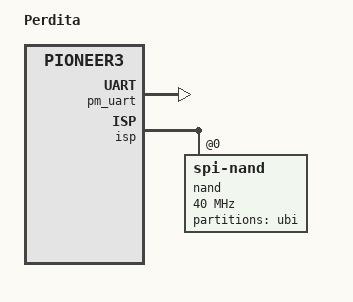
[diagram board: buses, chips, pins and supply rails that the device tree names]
// SPDX-License-Identifier: GPL-2.0
/*
 * Copyright (c) 2019 thingy.jp.
 * Author: Daniel Palmer <daniel@thingy.jp>
 */

/dts-v1/;
#include "mstar-pioneer3-ssd210.dtsi"

/ {
	model = "Perdita";
	compatible = "thingyjp,perdita", "sstar,pioneer3";

	aliases {
		serial0 = &pm_uart;
	};

	chosen {
		stdout-path = "serial0:115200n8";
		bootargs = "console=ttyS0,115200 clk_ignore_unused earlyprintk";
	};
};

&pm_uart {
	status = "okay";
};

&isp {
	status = "okay";
	nand: nand@0 {
		#address-cells = <1>;
		#size-cells = <1>;
		compatible = "spi-nand";
		reg = <0>;
		spi-max-frequency = <40000000>;
		spi-rx-bus-width = <1>;
		partitions {
			compatible = "fixed-partitions";
			#address-cells = <1>;
			#size-cells = <1>;
			ubi@400000 {
				label = "ubi";
				reg = <0x400000 0x7c00000>;
			};
		};
	};
};
